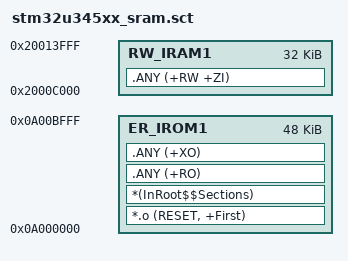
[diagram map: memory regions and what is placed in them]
; *************************************************************
; *** Scatter-Loading Description File generated by uVision ***
; *************************************************************

LR_IROM1 0x0A000000 0x0000C000  {    ; load region size_region
  ER_IROM1 0x0A000000 0x0000C000  {  ; load address = execution address
   *.o (RESET, +First)
   *(InRoot$$Sections)
   .ANY (+RO)
   .ANY (+XO)
  }
  RW_IRAM1 0x2000C000 0x00008000  {  ; RW data
   .ANY (+RW +ZI)
  }
}
